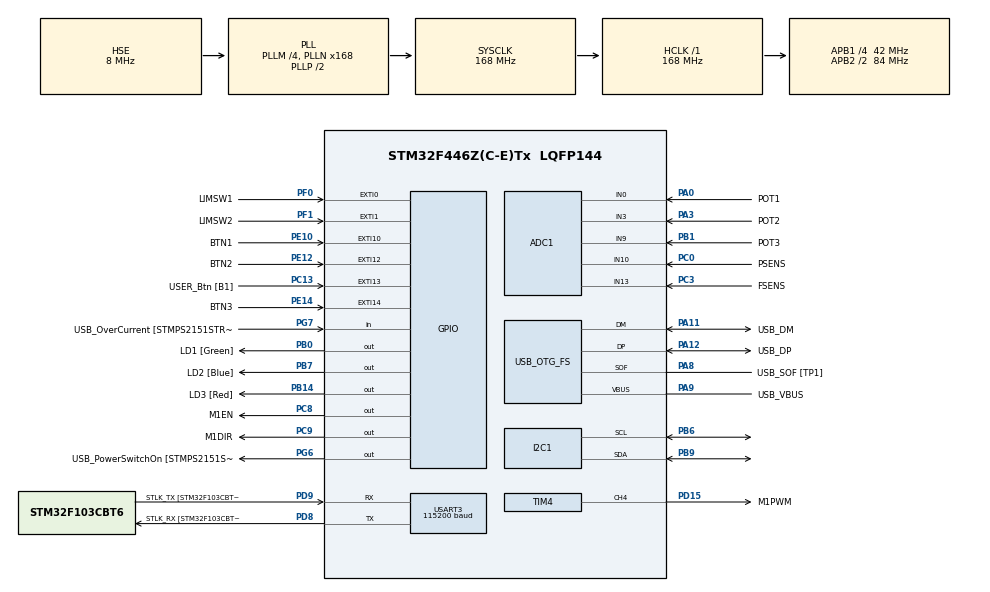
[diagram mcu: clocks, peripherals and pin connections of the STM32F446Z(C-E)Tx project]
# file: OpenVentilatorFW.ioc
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ADC1.Channel-3\#ChannelRegularConversion=ADC_CHANNEL_0
ADC1.Channel-4\#ChannelRegularConversion=ADC_CHANNEL_3
ADC1.Channel-5\#ChannelRegularConversion=ADC_CHANNEL_9
ADC1.Channel-6\#ChannelRegularConversion=ADC_CHANNEL_10
ADC1.Channel-7\#ChannelRegularConversion=ADC_CHANNEL_13
ADC1.ContinuousConvMode=ENABLE
ADC1.DMAContinuousRequests=ENABLE
ADC1.NbrOfConversion=5
ADC1.NbrOfConversionFlag=1
ADC1.Rank-3\#ChannelRegularConversion=1
ADC1.Rank-4\#ChannelRegularConversion=2
ADC1.Rank-5\#ChannelRegularConversion=3
ADC1.Rank-6\#ChannelRegularConversion=4
ADC1.Rank-7\#ChannelRegularConversion=5
ADC1.SamplingTime-3\#ChannelRegularConversion=ADC_SAMPLETIME_112CYCLES
ADC1.SamplingTime-4\#ChannelRegularConversion=ADC_SAMPLETIME_112CYCLES
ADC1.SamplingTime-5\#ChannelRegularConversion=ADC_SAMPLETIME_112CYCLES
ADC1.SamplingTime-6\#ChannelRegularConversion=ADC_SAMPLETIME_112CYCLES
ADC1.SamplingTime-7\#ChannelRegularConversion=ADC_SAMPLETIME_112CYCLES
ADC1.ScanConvMode=ENABLE
ADC1.master=1
Dma.ADC1.2.Direction=DMA_PERIPH_TO_MEMORY
Dma.ADC1.2.FIFOMode=DMA_FIFOMODE_DISABLE
Dma.ADC1.2.Instance=DMA2_Stream0
Dma.ADC1.2.MemDataAlignment=DMA_MDATAALIGN_WORD
Dma.ADC1.2.MemInc=DMA_MINC_ENABLE
Dma.ADC1.2.Mode=DMA_CIRCULAR
Dma.ADC1.2.PeriphDataAlignment=DMA_PDATAALIGN_WORD
Dma.ADC1.2.PeriphInc=DMA_PINC_DISABLE
Dma.ADC1.2.Priority=DMA_PRIORITY_MEDIUM
Dma.Request0=USART3_TX
Dma.Request1=USART3_RX
Dma.Request2=ADC1
Dma.USART3_RX.1.Direction=DMA_PERIPH_TO_MEMORY
Dma.USART3_RX.1.FIFOMode=DMA_FIFOMODE_DISABLE
Dma.USART3_RX.1.Instance=DMA1_Stream1
Dma.USART3_RX.1.MemDataAlignment=DMA_MDATAALIGN_BYTE
Dma.USART3_RX.1.MemInc=DMA_MINC_ENABLE
Dma.USART3_RX.1.Mode=DMA_CIRCULAR
Dma.USART3_RX.1.PeriphDataAlignment=DMA_PDATAALIGN_BYTE
Dma.USART3_RX.1.PeriphInc=DMA_PINC_DISABLE
Dma.USART3_RX.1.Priority=DMA_PRIORITY_VERY_HIGH
Dma.USART3_TX.0.Direction=DMA_MEMORY_TO_PERIPH
Dma.USART3_TX.0.FIFOMode=DMA_FIFOMODE_ENABLE
Dma.USART3_TX.0.FIFOThreshold=DMA_FIFO_THRESHOLD_FULL
Dma.USART3_TX.0.Instance=DMA1_Stream3
Dma.USART3_TX.0.MemBurst=DMA_MBURST_INC16
Dma.USART3_TX.0.MemDataAlignment=DMA_MDATAALIGN_BYTE
Dma.USART3_TX.0.MemInc=DMA_MINC_ENABLE
Dma.USART3_TX.0.Mode=DMA_NORMAL
Dma.USART3_TX.0.PeriphBurst=DMA_PBURST_SINGLE
Dma.USART3_TX.0.PeriphDataAlignment=DMA_PDATAALIGN_BYTE
Dma.USART3_TX.0.PeriphInc=DMA_PINC_DISABLE
Dma.USART3_TX.0.Priority=DMA_PRIORITY_VERY_HIGH
FREERTOS.INCLUDE_vTaskDelayUntil=1
FREERTOS.Tasks01=mainTask,0,128,StartDefaultTask,As weak,NULL,Dynamic,NULL,NULL
FREERTOS.configTICK_RATE_HZ=1000
Mcu.Family=STM32F4
Mcu.Name=STM32F446Z(C-E)Tx
Mcu.Package=LQFP144
Mcu.UserConstants=APB1Hz,42000000
NVIC.ADC_IRQn=true\:5\:0\:false\:false\:true\:true\:true\:true
NVIC.DMA1_Stream1_IRQn=true\:5\:0\:false\:false\:true\:true\:false\:true
NVIC.DMA1_Stream3_IRQn=true\:5\:0\:false\:false\:true\:true\:false\:true
NVIC.DMA2_Stream0_IRQn=true\:5\:0\:false\:false\:true\:true\:false\:true
NVIC.EXTI0_IRQn=true\:5\:0\:false\:false\:true\:true\:true\:true
NVIC.EXTI15_10_IRQn=true\:5\:0\:false\:false\:true\:true\:true\:true
NVIC.PriorityGroup=NVIC_PRIORITYGROUP_4
NVIC.TIM1_UP_TIM10_IRQn=true\:0\:0\:false\:false\:true\:false\:false\:true
NVIC.TIM2_IRQn=true\:5\:0\:false\:false\:true\:true\:true\:true
NVIC.TIM4_IRQn=true\:5\:0\:false\:false\:true\:true\:true\:true
NVIC.TimeBase=TIM1_UP_TIM10_IRQn
NVIC.TimeBaseIP=TIM1
NVIC.USART3_IRQn=true\:5\:0\:false\:false\:true\:true\:true\:true
PA0-WKUP.GPIO_Label=POT1
PA0-WKUP.Signal=ADCx_IN0
PA10.GPIO_Label=USB_ID
PA10.Signal=USB_OTG_FS_ID
PA11.GPIO_Label=USB_DM
PA11.Mode=Device_Only
PA11.Signal=USB_OTG_FS_DM
PA12.GPIO_Label=USB_DP
PA12.Mode=Device_Only
PA12.Signal=USB_OTG_FS_DP
PA13.GPIO_Label=TMS
PA13.Mode=Serial_Wire
PA13.Signal=SYS_JTMS-SWDIO
PA14.GPIO_Label=TCK
PA14.Mode=Serial_Wire
PA14.Signal=SYS_JTCK-SWCLK
PA3.GPIO_Label=POT2
PA3.Signal=ADCx_IN3
PA8.GPIO_Label=USB_SOF [TP1]
PA8.Mode=Activate_SOF_FS
PA8.Signal=USB_OTG_FS_SOF
PA9.GPIO_Label=USB_VBUS
PA9.Mode=Activate_VBUS
PA9.Signal=USB_OTG_FS_VBUS
PB0.GPIO_Label=LD1 [Green]
PB0.GPIO_Speed=GPIO_SPEED_FREQ_LOW
PB0.Signal=GPIO_Output
PB1.GPIO_Label=POT3
PB1.Signal=ADCx_IN9
PB14.GPIO_Label=LD3 [Red]
PB14.Signal=GPIO_Output
PB6.Mode=I2C
PB6.Signal=I2C1_SCL
PB7.GPIO_Label=LD2 [Blue]
PB7.Signal=GPIO_Output
PB9.Mode=I2C
PB9.Signal=I2C1_SDA
PC0.GPIO_Label=PSENS
PC0.Signal=ADCx_IN10
PC13.GPIO_Label=USER_Btn [B1]
PC13.Signal=GPXTI13
PC14-OSC32_IN.Mode=LSE-External-Oscillator
PC14-OSC32_IN.Signal=RCC_OSC32_IN
PC15-OSC32_OUT.Mode=LSE-External-Oscillator
PC15-OSC32_OUT.Signal=RCC_OSC32_OUT
PC3.GPIO_Label=FSENS
PC3.Signal=ADCx_IN13
PC8.GPIO_Label=M1EN
PC8.GPIO_Speed=GPIO_SPEED_FREQ_MEDIUM
PC8.PinState=GPIO_PIN_SET
PC8.Signal=GPIO_Output
PC9.GPIO_Label=M1DIR
PC9.GPIO_Speed=GPIO_SPEED_FREQ_MEDIUM
PC9.Signal=GPIO_Output
PD15.GPIO_Label=M1PWM
PD15.Signal=S_TIM4_CH4
PD8.GPIO_Label=STLK_RX [STM32F103CBT6_PA3]
PD8.Mode=Asynchronous
PD8.Signal=USART3_TX
PD9.GPIO_Label=STLK_TX [STM32F103CBT6_PA2]
PD9.Mode=Asynchronous
PD9.Signal=USART3_RX
PE10.GPIO_Label=BTN1
PE10.GPIO_ModeDefaultEXTI=GPIO_MODE_IT_FALLING
PE10.GPIO_PuPd=GPIO_PULLUP
PE10.Signal=GPXTI10
PE12.GPIO_Label=BTN2
PE12.GPIO_ModeDefaultEXTI=GPIO_MODE_IT_FALLING
PE12.GPIO_PuPd=GPIO_PULLUP
PE12.Signal=GPXTI12
PE14.GPIO_Label=BTN3
PE14.GPIO_ModeDefaultEXTI=GPIO_MODE_IT_FALLING
PE14.GPIO_PuPd=GPIO_PULLUP
PE14.Signal=GPXTI14
PF0.GPIO_Label=LIMSW1
PF0.GPIO_ModeDefaultEXTI=GPIO_MODE_IT_FALLING
PF0.Signal=GPXTI0
PF1.GPIO_Label=LIMSW2
PF1.GPIO_ModeDefaultEXTI=GPIO_MODE_IT_FALLING
PF1.Signal=GPXTI1
PG6.GPIO_Label=USB_PowerSwitchOn [STMPS2151STR_EN]
PG6.Signal=GPIO_Output
PG7.GPIO_Label=USB_OverCurrent [STMPS2151STR_FAULT]
PG7.Signal=GPIO_Input
PH0-OSC_IN.GPIO_Label=MCO [STM32F103CBT6_PA8]
PH0-OSC_IN.Mode=HSE-External-Clock-Source
PH0-OSC_IN.Signal=RCC_OSC_IN
PH1-OSC_OUT.Mode=HSE-External-Clock-Source
PH1-OSC_OUT.Signal=RCC_OSC_OUT
ProjectManager.HeapSize=0x200
ProjectManager.StackSize=0x400
ProjectManager.TargetToolchain=STM32CubeIDE
RCC.48MHZClocksFreq_Value=24000000
RCC.AHBFreq_Value=168000000
RCC.APB1CLKDivider=RCC_HCLK_DIV4
RCC.APB1Freq_Value=42000000
RCC.APB1TimFreq_Value=84000000
RCC.APB2CLKDivider=RCC_HCLK_DIV2
RCC.APB2Freq_Value=84000000
RCC.APB2TimFreq_Value=168000000
RCC.CortexFreq_Value=168000000
RCC.HCLKFreq_Value=168000000
RCC.HSE_VALUE=8000000
RCC.HSI_VALUE=16000000
RCC.PLLM=4
RCC.PLLMUL=RCC_PLL_MUL9
RCC.PLLN=168
RCC.PLLQ=7
RCC.PRESCALERUSB=RCC_USBCLKSOURCE_PLL_DIV1_5
RCC.SYSCLKFreq_VALUE=168000000
RCC.SYSCLKSource=RCC_SYSCLKSOURCE_PLLCLK
RCC.SYSCLKSourceVirtual=RCC_SYSCLKSOURCE_PLLCLK
RCC.USBFreq_Value=48000000
RCC.VCOOutputFreq_Value=336000000
SH.ADCx_IN0.0=ADC1_IN0,IN0
SH.ADCx_IN10.0=ADC1_IN10,IN10
SH.ADCx_IN13.0=ADC1_IN13,IN13
SH.ADCx_IN3.0=ADC1_IN3,IN3
SH.ADCx_IN9.0=ADC1_IN9,IN9
SH.S_TIM4_CH4.0=TIM4_CH4,PWM Generation4 CH4
TIM2.AutoReloadPreload=TIM_AUTORELOAD_PRELOAD_ENABLE
TIM2.Period=42
TIM2.Prescaler=0
TIM2.TIM_MasterOutputTrigger=TIM_TRGO_RESET
TIM4.AutoReloadPreload=TIM_AUTORELOAD_PRELOAD_ENABLE
TIM4.Channel-PWM\ Generation4\ CH4=TIM_CHANNEL_4
TIM4.OCFastMode_PWM-PWM\ Generation4\ CH4=TIM_OCFAST_ENABLE
TIM4.Period=1000
TIM4.Prescaler=840
USART3.BaudRate=115200
USART3.VirtualMode=VM_ASYNC
USB_OTG_FS.VirtualMode=Device_Only
VP_FREERTOS_VS_CMSIS_V1.Mode=CMSIS_V1
VP_SYS_VS_tim1.Mode=TIM1
VP_TIM2_VS_ClockSourceINT.Mode=Internal
VP_TIM4_VS_ClockSourceINT.Mode=Internal
board=NUCLEO-F446ZE

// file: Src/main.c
/* USER CODE BEGIN Header */
/**
  ******************************************************************************
  * @file           : main.c
  * @brief          : Main program body
  ******************************************************************************
  * @attention
  *
  * <h2><center>&copy; Copyright (c) 2020 STMicroelectronics.
  * All rights reserved.</center></h2>
  *
  * This software component is licensed by ST under BSD 3-Clause license,
  * the "License"; You may not use this file except in compliance with the
  * License. You may obtain a copy of the License at:
  *                        opensource.org/licenses/BSD-3-Clause
  *
  ******************************************************************************
  */
/* USER CODE END Header */

#include "main.h"
#include "cmsis_os.h"

ADC_HandleTypeDef hadc1;
DMA_HandleTypeDef hdma_adc1;

I2C_HandleTypeDef hi2c1;

TIM_HandleTypeDef htim2;
TIM_HandleTypeDef htim4;

UART_HandleTypeDef huart3;
DMA_HandleTypeDef hdma_usart3_tx;
DMA_HandleTypeDef hdma_usart3_rx;

PCD_HandleTypeDef hpcd_USB_OTG_FS;

osThreadId mainTaskHandle;
/* USER CODE BEGIN PV */
__IO uint64_t uwTickMicroseconds;
extern TIM_OC_InitTypeDef sConfigOCtim4;

/* USER CODE END PV */

void SystemClock_Config(void);
static void MX_GPIO_Init(void);
static void MX_DMA_Init(void);
static void MX_USART3_UART_Init(void);
static void MX_USB_OTG_FS_PCD_Init(void);
static void MX_ADC1_Init(void);
static void MX_TIM2_Init(void);
static void MX_TIM4_Init(void);
static void MX_I2C1_Init(void);
void StartDefaultTask(void const * argument);

int main(void)
{

  /* MCU Configuration--------------------------------------------------------*/

  /* Reset of all peripherals, Initializes the Flash interface and the Systick. */
  HAL_Init();

  /* USER CODE BEGIN Init */
  dwt_init();
  /* USER CODE END Init */

  /* Configure the system clock */
  SystemClock_Config();

  /* Initialize all configured peripherals */
  MX_GPIO_Init();
  MX_DMA_Init();
  MX_USART3_UART_Init();
  MX_USB_OTG_FS_PCD_Init();
  MX_ADC1_Init();
  MX_TIM2_Init();
  MX_TIM4_Init();
  MX_I2C1_Init();

  /* Create the thread(s) */
  /* definition and creation of mainTask */
  osThreadDef(mainTask, StartDefaultTask, osPriorityNormal, 0, 128);
  mainTaskHandle = osThreadCreate(osThread(mainTask), NULL);

  /* USER CODE BEGIN RTOS_THREADS */
  /* add threads, ... */
  StartOpenVentilator();
  /* USER CODE END RTOS_THREADS */

  /* Start scheduler */
  osKernelStart();

  /* We should never get here as control is now taken by the scheduler */

  /* Infinite loop */
  while (1)
  {

  }
}

void SystemClock_Config(void)
{
  RCC_OscInitTypeDef RCC_OscInitStruct = {0};
  RCC_ClkInitTypeDef RCC_ClkInitStruct = {0};
  RCC_PeriphCLKInitTypeDef PeriphClkInitStruct = {0};

  /** Configure the main internal regulator output voltage
  */
  __HAL_RCC_PWR_CLK_ENABLE();
  __HAL_PWR_VOLTAGESCALING_CONFIG(PWR_REGULATOR_VOLTAGE_SCALE1);
  /** Initializes the CPU, AHB and APB busses clocks
  */
  RCC_OscInitStruct.OscillatorType = RCC_OSCILLATORTYPE_HSE;
  RCC_OscInitStruct.HSEState = RCC_HSE_BYPASS;
  RCC_OscInitStruct.PLL.PLLState = RCC_PLL_ON;
  RCC_OscInitStruct.PLL.PLLSource = RCC_PLLSOURCE_HSE;
  RCC_OscInitStruct.PLL.PLLM = 4;
  RCC_OscInitStruct.PLL.PLLN = 168;
  RCC_OscInitStruct.PLL.PLLP = RCC_PLLP_DIV2;
  RCC_OscInitStruct.PLL.PLLQ = 7;
  RCC_OscInitStruct.PLL.PLLR = 2;
  if (HAL_RCC_OscConfig(&RCC_OscInitStruct) != HAL_OK)
  {
    Error_Handler();
  }
  /** Initializes the CPU, AHB and APB busses clocks
  */
  RCC_ClkInitStruct.ClockType = RCC_CLOCKTYPE_HCLK|RCC_CLOCKTYPE_SYSCLK
                              |RCC_CLOCKTYPE_PCLK1|RCC_CLOCKTYPE_PCLK2;
  RCC_ClkInitStruct.SYSCLKSource = RCC_SYSCLKSOURCE_PLLCLK;
  RCC_ClkInitStruct.AHBCLKDivider = RCC_SYSCLK_DIV1;
  RCC_ClkInitStruct.APB1CLKDivider = RCC_HCLK_DIV4;
  RCC_ClkInitStruct.APB2CLKDivider = RCC_HCLK_DIV2;

  if (HAL_RCC_ClockConfig(&RCC_ClkInitStruct, FLASH_LATENCY_5) != HAL_OK)
  {
    Error_Handler();
  }
  PeriphClkInitStruct.PeriphClockSelection = RCC_PERIPHCLK_CLK48;
  PeriphClkInitStruct.Clk48ClockSelection = RCC_CLK48CLKSOURCE_PLLQ;
  if (HAL_RCCEx_PeriphCLKConfig(&PeriphClkInitStruct) != HAL_OK)
  {
    Error_Handler();
  }
}

static void MX_ADC1_Init(void)
{

  ADC_ChannelConfTypeDef sConfig = {0};

  /** Configure the global features of the ADC (Clock, Resolution, Data Alignment and number of conversion)
  */
  hadc1.Instance = ADC1;
  hadc1.Init.ClockPrescaler = ADC_CLOCK_SYNC_PCLK_DIV4;
  hadc1.Init.Resolution = ADC_RESOLUTION_12B;
  hadc1.Init.ScanConvMode = ENABLE;
  hadc1.Init.ContinuousConvMode = ENABLE;
  hadc1.Init.DiscontinuousConvMode = DISABLE;
  hadc1.Init.ExternalTrigConvEdge = ADC_EXTERNALTRIGCONVEDGE_NONE;
  hadc1.Init.ExternalTrigConv = ADC_SOFTWARE_START;
  hadc1.Init.DataAlign = ADC_DATAALIGN_RIGHT;
  hadc1.Init.NbrOfConversion = 5;
  hadc1.Init.DMAContinuousRequests = ENABLE;
  hadc1.Init.EOCSelection = ADC_EOC_SINGLE_CONV;
  if (HAL_ADC_Init(&hadc1) != HAL_OK)
  {
    Error_Handler();
  }
  /** Configure for the selected ADC regular channel its corresponding rank in the sequencer and its sample time.
  */
  sConfig.Channel = ADC_CHANNEL_0;
  sConfig.Rank = 1;
  sConfig.SamplingTime = ADC_SAMPLETIME_112CYCLES;
  if (HAL_ADC_ConfigChannel(&hadc1, &sConfig) != HAL_OK)
  {
    Error_Handler();
  }
  /** Configure for the selected ADC regular channel its corresponding rank in the sequencer and its sample time.
  */
  sConfig.Channel = ADC_CHANNEL_3;
  sConfig.Rank = 2;
  if (HAL_ADC_ConfigChannel(&hadc1, &sConfig) != HAL_OK)
  {
    Error_Handler();
  }
  /** Configure for the selected ADC regular channel its corresponding rank in the sequencer and its sample time.
  */
  sConfig.Channel = ADC_CHANNEL_9;
  sConfig.Rank = 3;
  if (HAL_ADC_ConfigChannel(&hadc1, &sConfig) != HAL_OK)
  {
    Error_Handler();
  }
  /** Configure for the selected ADC regular channel its corresponding rank in the sequencer and its sample time.
  */
  sConfig.Channel = ADC_CHANNEL_10;
  sConfig.Rank = 4;
  if (HAL_ADC_ConfigChannel(&hadc1, &sConfig) != HAL_OK)
  {
    Error_Handler();
  }
  /** Configure for the selected ADC regular channel its corresponding rank in the sequencer and its sample time.
  */
  sConfig.Channel = ADC_CHANNEL_13;
  sConfig.Rank = 5;
  if (HAL_ADC_ConfigChannel(&hadc1, &sConfig) != HAL_OK)
  {
    Error_Handler();
  }

}

static void MX_I2C1_Init(void)
{

  hi2c1.Instance = I2C1;
  hi2c1.Init.ClockSpeed = 100000;
  hi2c1.Init.DutyCycle = I2C_DUTYCYCLE_2;
  hi2c1.Init.OwnAddress1 = 0;
  hi2c1.Init.AddressingMode = I2C_ADDRESSINGMODE_7BIT;
  hi2c1.Init.DualAddressMode = I2C_DUALADDRESS_DISABLE;
  hi2c1.Init.OwnAddress2 = 0;
  hi2c1.Init.GeneralCallMode = I2C_GENERALCALL_DISABLE;
  hi2c1.Init.NoStretchMode = I2C_NOSTRETCH_DISABLE;
  if (HAL_I2C_Init(&hi2c1) != HAL_OK)
  {
    Error_Handler();
  }

}

static void MX_TIM2_Init(void)
{

  TIM_ClockConfigTypeDef sClockSourceConfig = {0};
  TIM_MasterConfigTypeDef sMasterConfig = {0};

  htim2.Instance = TIM2;
  htim2.Init.Prescaler = 0;
  htim2.Init.CounterMode = TIM_COUNTERMODE_UP;
  htim2.Init.Period = 42;
  htim2.Init.ClockDivision = TIM_CLOCKDIVISION_DIV1;
  htim2.Init.AutoReloadPreload = TIM_AUTORELOAD_PRELOAD_ENABLE;
  if (HAL_TIM_Base_Init(&htim2) != HAL_OK)
  {
    Error_Handler();
  }
  sClockSourceConfig.ClockSource = TIM_CLOCKSOURCE_INTERNAL;
  if (HAL_TIM_ConfigClockSource(&htim2, &sClockSourceConfig) != HAL_OK)
  {
    Error_Handler();
  }
  sMasterConfig.MasterOutputTrigger = TIM_TRGO_RESET;
  sMasterConfig.MasterSlaveMode = TIM_MASTERSLAVEMODE_DISABLE;
  if (HAL_TIMEx_MasterConfigSynchronization(&htim2, &sMasterConfig) != HAL_OK)
  {
    Error_Handler();
  }
  /* USER CODE BEGIN TIM2_Init 2 */
//  HAL_TIM_Base_Start_IT(&htim2);
  /* USER CODE END TIM2_Init 2 */

}

static void MX_TIM4_Init(void)
{

  TIM_ClockConfigTypeDef sClockSourceConfig = {0};
  TIM_MasterConfigTypeDef sMasterConfig = {0};
  TIM_OC_InitTypeDef sConfigOC = {0};

  htim4.Instance = TIM4;
  htim4.Init.Prescaler = 840;
  htim4.Init.CounterMode = TIM_COUNTERMODE_UP;
  htim4.Init.Period = 1000;
  htim4.Init.ClockDivision = TIM_CLOCKDIVISION_DIV1;
  htim4.Init.AutoReloadPreload = TIM_AUTORELOAD_PRELOAD_ENABLE;
  if (HAL_TIM_Base_Init(&htim4) != HAL_OK)
  {
    Error_Handler();
  }
  sClockSourceConfig.ClockSource = TIM_CLOCKSOURCE_INTERNAL;
  if (HAL_TIM_ConfigClockSource(&htim4, &sClockSourceConfig) != HAL_OK)
  {
    Error_Handler();
  }
  if (HAL_TIM_PWM_Init(&htim4) != HAL_OK)
  {
    Error_Handler();
  }
  sMasterConfig.MasterOutputTrigger = TIM_TRGO_RESET;
  sMasterConfig.MasterSlaveMode = TIM_MASTERSLAVEMODE_DISABLE;
  if (HAL_TIMEx_MasterConfigSynchronization(&htim4, &sMasterConfig) != HAL_OK)
  {
    Error_Handler();
  }
  sConfigOC.OCMode = TIM_OCMODE_PWM1;
  sConfigOC.Pulse = 0;
  sConfigOC.OCPolarity = TIM_OCPOLARITY_HIGH;
  sConfigOC.OCFastMode = TIM_OCFAST_ENABLE;
  if (HAL_TIM_PWM_ConfigChannel(&htim4, &sConfigOC, TIM_CHANNEL_4) != HAL_OK)
  {
    Error_Handler();
  }
  /* USER CODE BEGIN TIM4_Init 2 */
  sConfigOCtim4  = sConfigOC;
  /* USER CODE END TIM4_Init 2 */
  HAL_TIM_MspPostInit(&htim4);

}

static void MX_USART3_UART_Init(void)
{

  huart3.Instance = USART3;
  huart3.Init.BaudRate = 115200;
  huart3.Init.WordLength = UART_WORDLENGTH_8B;
  huart3.Init.StopBits = UART_STOPBITS_1;
  huart3.Init.Parity = UART_PARITY_NONE;
  huart3.Init.Mode = UART_MODE_TX_RX;
  huart3.Init.HwFlowCtl = UART_HWCONTROL_NONE;
  huart3.Init.OverSampling = UART_OVERSAMPLING_16;
  if (HAL_UART_Init(&huart3) != HAL_OK)
  {
    Error_Handler();
  }

}

static void MX_USB_OTG_FS_PCD_Init(void)
{

  hpcd_USB_OTG_FS.Instance = USB_OTG_FS;
  hpcd_USB_OTG_FS.Init.dev_endpoints = 6;
  hpcd_USB_OTG_FS.Init.speed = PCD_SPEED_FULL;
  hpcd_USB_OTG_FS.Init.dma_enable = DISABLE;
  hpcd_USB_OTG_FS.Init.phy_itface = PCD_PHY_EMBEDDED;
  hpcd_USB_OTG_FS.Init.Sof_enable = ENABLE;
  hpcd_USB_OTG_FS.Init.low_power_enable = DISABLE;
  hpcd_USB_OTG_FS.Init.lpm_enable = DISABLE;
  hpcd_USB_OTG_FS.Init.vbus_sensing_enable = ENABLE;
  hpcd_USB_OTG_FS.Init.use_dedicated_ep1 = DISABLE;
  if (HAL_PCD_Init(&hpcd_USB_OTG_FS) != HAL_OK)
  {
    Error_Handler();
  }

}

static void MX_DMA_Init(void)
{

  /* DMA controller clock enable */
  __HAL_RCC_DMA1_CLK_ENABLE();
  __HAL_RCC_DMA2_CLK_ENABLE();

  /* DMA interrupt init */
  /* DMA1_Stream1_IRQn interrupt configuration */
  HAL_NVIC_SetPriority(DMA1_Stream1_IRQn, 5, 0);
  HAL_NVIC_EnableIRQ(DMA1_Stream1_IRQn);
  /* DMA1_Stream3_IRQn interrupt configuration */
  HAL_NVIC_SetPriority(DMA1_Stream3_IRQn, 5, 0);
  HAL_NVIC_EnableIRQ(DMA1_Stream3_IRQn);
  /* DMA2_Stream0_IRQn interrupt configuration */
  HAL_NVIC_SetPriority(DMA2_Stream0_IRQn, 5, 0);
  HAL_NVIC_EnableIRQ(DMA2_Stream0_IRQn);

}

static void MX_GPIO_Init(void)
{
  GPIO_InitTypeDef GPIO_InitStruct = {0};

  /* GPIO Ports Clock Enable */
  __HAL_RCC_GPIOC_CLK_ENABLE();
  __HAL_RCC_GPIOF_CLK_ENABLE();
  __HAL_RCC_GPIOH_CLK_ENABLE();
  __HAL_RCC_GPIOA_CLK_ENABLE();
  __HAL_RCC_GPIOB_CLK_ENABLE();
  __HAL_RCC_GPIOE_CLK_ENABLE();
  __HAL_RCC_GPIOD_CLK_ENABLE();
  __HAL_RCC_GPIOG_CLK_ENABLE();

  /*Configure GPIO pin Output Level */
  HAL_GPIO_WritePin(GPIOB, LD1_Pin|LD3_Pin|LD2_Pin, GPIO_PIN_RESET);

  /*Configure GPIO pin Output Level */
  HAL_GPIO_WritePin(USB_PowerSwitchOn_GPIO_Port, USB_PowerSwitchOn_Pin, GPIO_PIN_RESET);

  /*Configure GPIO pin Output Level */
  HAL_GPIO_WritePin(M1EN_GPIO_Port, M1EN_Pin, GPIO_PIN_SET);

  /*Configure GPIO pin Output Level */
  HAL_GPIO_WritePin(M1DIR_GPIO_Port, M1DIR_Pin, GPIO_PIN_RESET);

  /*Configure GPIO pin : USER_Btn_Pin */
  GPIO_InitStruct.Pin = USER_Btn_Pin;
  GPIO_InitStruct.Mode = GPIO_MODE_IT_RISING;
  GPIO_InitStruct.Pull = GPIO_NOPULL;
  HAL_GPIO_Init(USER_Btn_GPIO_Port, &GPIO_InitStruct);

  /*Configure GPIO pins : LIMSW1_Pin LIMSW2_Pin */
  GPIO_InitStruct.Pin = LIMSW1_Pin|LIMSW2_Pin;
  GPIO_InitStruct.Mode = GPIO_MODE_IT_FALLING;
  GPIO_InitStruct.Pull = GPIO_NOPULL;
  HAL_GPIO_Init(GPIOF, &GPIO_InitStruct);

  /*Configure GPIO pins : LD1_Pin LD3_Pin LD2_Pin */
  GPIO_InitStruct.Pin = LD1_Pin|LD3_Pin|LD2_Pin;
  GPIO_InitStruct.Mode = GPIO_MODE_OUTPUT_PP;
  GPIO_InitStruct.Pull = GPIO_NOPULL;
  GPIO_InitStruct.Speed = GPIO_SPEED_FREQ_LOW;
  HAL_GPIO_Init(GPIOB, &GPIO_InitStruct);

  /*Configure GPIO pins : BTN1_Pin BTN2_Pin BTN3_Pin */
  GPIO_InitStruct.Pin = BTN1_Pin|BTN2_Pin|BTN3_Pin;
  GPIO_InitStruct.Mode = GPIO_MODE_IT_FALLING;
  GPIO_InitStruct.Pull = GPIO_PULLUP;
  HAL_GPIO_Init(GPIOE, &GPIO_InitStruct);

  /*Configure GPIO pin : USB_PowerSwitchOn_Pin */
  GPIO_InitStruct.Pin = USB_PowerSwitchOn_Pin;
  GPIO_InitStruct.Mode = GPIO_MODE_OUTPUT_PP;
  GPIO_InitStruct.Pull = GPIO_NOPULL;
  GPIO_InitStruct.Speed = GPIO_SPEED_FREQ_LOW;
  HAL_GPIO_Init(USB_PowerSwitchOn_GPIO_Port, &GPIO_InitStruct);

  /*Configure GPIO pin : USB_OverCurrent_Pin */
  GPIO_InitStruct.Pin = USB_OverCurrent_Pin;
  GPIO_InitStruct.Mode = GPIO_MODE_INPUT;
  GPIO_InitStruct.Pull = GPIO_NOPULL;
  HAL_GPIO_Init(USB_OverCurrent_GPIO_Port, &GPIO_InitStruct);

  /*Configure GPIO pins : M1EN_Pin M1DIR_Pin */
  GPIO_InitStruct.Pin = M1EN_Pin|M1DIR_Pin;
  GPIO_InitStruct.Mode = GPIO_MODE_OUTPUT_PP;
  GPIO_InitStruct.Pull = GPIO_NOPULL;
  GPIO_InitStruct.Speed = GPIO_SPEED_FREQ_MEDIUM;
  HAL_GPIO_Init(GPIOC, &GPIO_InitStruct);

  /* EXTI interrupt init*/
  HAL_NVIC_SetPriority(EXTI0_IRQn, 5, 0);
  HAL_NVIC_EnableIRQ(EXTI0_IRQn);

  HAL_NVIC_SetPriority(EXTI15_10_IRQn, 5, 0);
  HAL_NVIC_EnableIRQ(EXTI15_10_IRQn);

}

__weak void StartDefaultTask(void const * argument)
{
  for(;;)
  {
    osDelay(1);
  }
}

void HAL_TIM_PeriodElapsedCallback(TIM_HandleTypeDef *htim)
{
  if (htim->Instance == TIM1) {
    HAL_IncTick();
  }
  /* USER CODE BEGIN Callback 1 */
  if (htim->Instance == TIM2) {
	  uwTickMicroseconds++;
  }
  /* USER CODE END Callback 1 */
}

void Error_Handler(void)
{
}

/************************ (C) COPYRIGHT STMicroelectronics *****END OF FILE****/
